# R7FA4M3AF register map
Vendor: Renesas Electronics Corporation; Series: RA4; File version: 1.40.00
CPU: CM33 r0p4, little endian, MPU, FPU, VTOR, 4 interrupt priority bits, 96 interrupts
Registers are 8-bit, read-write, reset 0x0 unless marked. A register's access mark holds for its fields unless they carry their own. Offsets are from the block's base; [hi:lo] are bit positions; {n}, {i} and the like mark numbered series.

## DAC12 — 12-bit D/A converter
Base 0x40171000
{0x0+2i} DADR{i} (i=0..1) 16-bit — D/A Data Register {i}
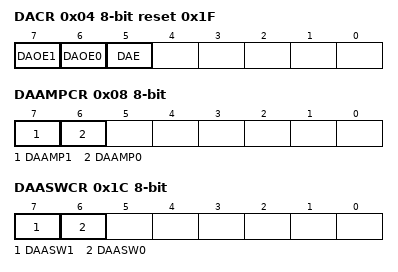
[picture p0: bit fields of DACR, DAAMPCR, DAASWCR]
0x04 DACR reset 0x1F — D/A Control Register
  [7] DAOE1 — D/A Output Enable 1
  [6] DAOE0 — D/A Output Enable 0
  [5] DAE — D/A Enable
0x05 DADPR — DADRn Format Select Register
  [7] DPSEL — DADRn Format Select
0x06 DAADSCR — D/A A/D Synchronous Start Control Register
  [7] DAADST — D/A A/D Synchronous Conversion
0x08 DAAMPCR — D/A Output Amplifier Control Register
  [7] DAAMP1 — Amplifier Control 1
  [6] DAAMP0 — Amplifier Control 0
0x1C DAASWCR — D/A Amplifier Stabilization Wait Control Register
  [7] DAASW1 — D/A Amplifier Stabilization Wait 1
  [6] DAASW0 — D/A Amplifier Stabilization Wait 0
0x10C0 DAADUSR — D/A A/D Synchronous Unit Select Register
  [1] AMADSEL1 — A/D Unit 1 Select

## TSD — Temperature Sensor Calibration Data
Base 0x407FB000
0x17C TSCDR 32-bit ro (reset mask 0xFFFF0000) — Temperature Sensor Calibration Data Register
  [15:0] TSCDR — Temperature Sensor Calibration Data

## FLAD — Data Flash
Base 0x407FC000
0x40 FCKMHZ reset 0x3C — Data Flash Access Frequency Register

## FACI — Flash/CPU Interface
Base 0x407FE000
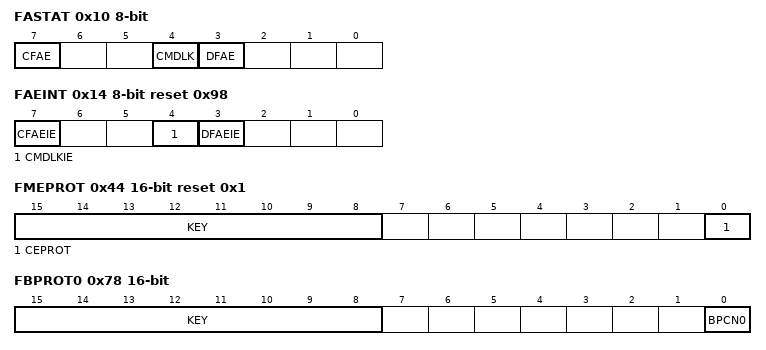
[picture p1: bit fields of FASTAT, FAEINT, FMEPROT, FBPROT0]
0x10 FASTAT — Flash Access Status Register
  [7] CFAE — Code Flash Memory Access Violation Flag
  [4] CMDLK ro — Command Lock Flag
  [3] DFAE — Data Flash Memory Access Violation Flag
0x14 FAEINT reset 0x98 — Flash Access Error Interrupt Enable Register
  [7] CFAEIE — Code Flash Memory Access Violation Interrupt Enable
  [4] CMDLKIE — Command Lock Interrupt Enable
  [3] DFAEIE — Data Flash Memory Access Violation Interrupt Enable
0x18 FRDYIE — Flash Ready Interrupt Enable Register
  [0] FRDYIE — Flash Ready Interrupt Enable
0x30 FSADDR 32-bit — FACI Command Start Address Register
  [31:0] FSADDR — Start Address for FACI Command Processing
0x34 FEADDR 32-bit — FACI Command End Address Register
  [31:0] FEADDR — End Address for FACI Command Processing
0x44 FMEPROT 16-bit reset 0x1 — Flash P/E Mode Entry Protection Register
  [15:8] KEY wo — Key Code
  [0] CEPROT — Code Flash P/E Mode Entry Protection
0x78 FBPROT0 16-bit — Flash Block Protection Register
  [15:8] KEY wo — Key Code
  [0] BPCN0 — Block Protection for Non,secure Cancel
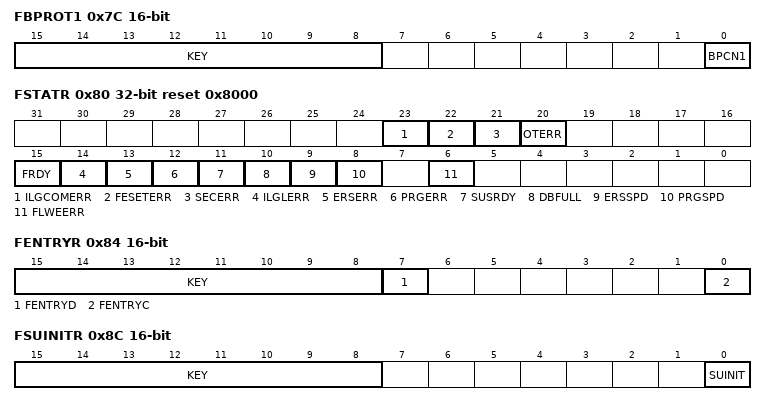
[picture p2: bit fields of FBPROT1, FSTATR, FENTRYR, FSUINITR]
0x7C FBPROT1 16-bit — Flash Block Protection for Secure Register
  [15:8] KEY wo — Key Code
  [0] BPCN1 — Block Protection for Secure Cancel
0x80 FSTATR 32-bit reset 0x8000 — Flash Status Register
  [23] ILGCOMERR ro — Illegal Command Error
  [22] FESETERR ro — FENTRY Setting Error
  [21] SECERR ro — Security Error
  [20] OTERR ro — Other Error
  [15] FRDY ro — Flash Ready Flag
  [14] ILGLERR ro — Illegal Command Error Flag
  [13] ERSERR ro — Erasure Error Flag
  [12] PRGERR ro — Programming Error Flag
  [11] SUSRDY ro — Suspend Ready Flag
  [10] DBFULL ro — Data Buffer Full Flag
  [9] ERSSPD ro — Erasure Suspend Status Flag
  [8] PRGSPD ro — Programming Suspend Status Flag
  [6] FLWEERR ro — Flash Write/Erase Protect Error Flag
0x84 FENTRYR 16-bit — Flash P/E Mode Entry Register
  [15:8] KEY wo — Key Code
  [7] FENTRYD — Data Flash P/E Mode Entry
  [0] FENTRYC — Code Flash P/E Mode Entry
0x8C FSUINITR 16-bit — Flash Sequencer Setup Initialization Register
  [15:8] KEY wo — Key Code
  [0] SUINIT — Set,Up Initialization
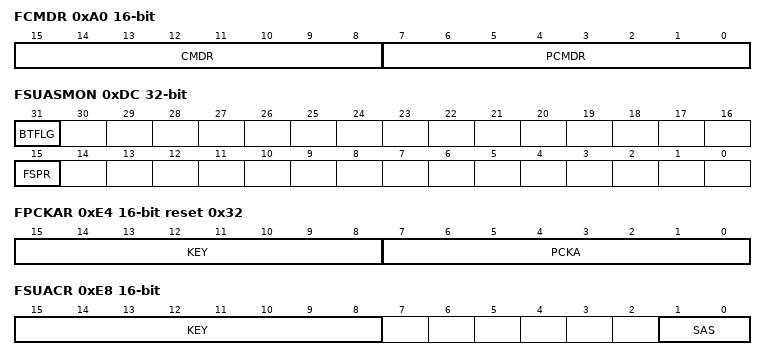
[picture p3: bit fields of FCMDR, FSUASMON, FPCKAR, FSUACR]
0xA0 FCMDR 16-bit ro — FACI Command Register
  [15:8] CMDR — Command Flag
  [7:0] PCMDR — Pre,command Flag
0xD0 FBCCNT — Blank Check Control Register
  [0] BCDIR — Blank Check Direction
0xD4 FBCSTAT — Blank Check Status Register
  [0] BCST ro — Blank Check Status Flag
0xD8 FPSADDR 32-bit — Data Flash Programming Start Address Register
  [16:0] PSADR ro — Programmed Area Start Address
0xDC FSUASMON 32-bit ro (reset mask 0x7FFF7FFF) — Flash Startup Area Select Monitor Register
  [31] BTFLG — Flag of Startup Area Select for Boot Swap
  [15] FSPR — Protection Programming Flag to set Boot Flag and Startup Area Control
0xE0 FCPSR 16-bit — Flash Sequencer Processing Switching Register
  [0] ESUSPMD — Erasure Suspend Mode
0xE4 FPCKAR 16-bit reset 0x32 — Flash Sequencer Processing Clock Notification Register
  [15:8] KEY wo — Key Code
  [7:0] PCKA — Flash Sequencer Operating Clock Notification
0xE8 FSUACR 16-bit — Flash Startup Area Control Register
  [15:8] KEY wo — Key Code
  [1:0] SAS — Startup Area Select

## QSPI — Quad Serial Peripheral Interface
Base 0x64000000
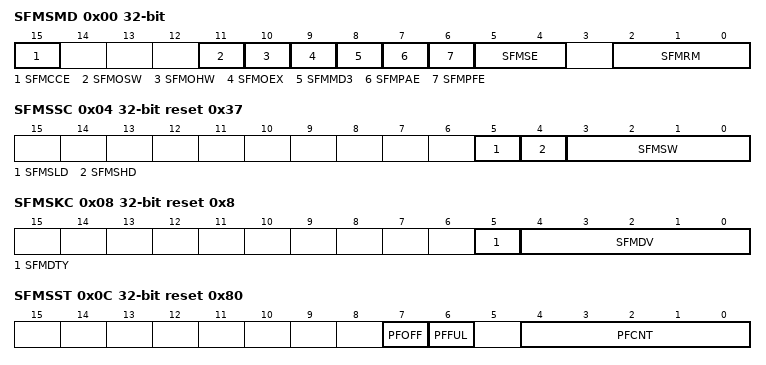
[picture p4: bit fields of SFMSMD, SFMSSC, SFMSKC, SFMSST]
0x00 SFMSMD 32-bit — Transfer Mode Control Register
  [15] SFMCCE — Read instruction code select
  [11] SFMOSW — Setup time adjustment for serial transmission
  [10] SFMOHW — Hold time adjustment for serial transmission
  [9] SFMOEX — Extension select for the I/O buffer output enable signal for the serial interface
  [8] SFMMD3 — SPI mode select.
  [7] SFMPAE — Function select for stopping prefetch at locations other than on byte boundaries
  [6] SFMPFE — Prefetch function select
  [5:4] SFMSE — QSSL extension function select after SPI bus access
  [2:0] SFMRM — Serial interface read mode select
0x04 SFMSSC 32-bit reset 0x37 — Chip Selection Control Register
  [5] SFMSLD — QSSL Signal Setup Time
  [4] SFMSHD — QSSL Signal Hold Time
  [3:0] SFMSW — Minimum High,level Width Select for QSSL Signal
0x08 SFMSKC 32-bit reset 0x8 — Clock Control Register
  [5] SFMDTY — Duty ratio correction function select for the QSPCLK signal when devided by an odd number
  [4:0] SFMDV — Serial interface reference cycle select. (Pay attention to irregularities.)
0x0C SFMSST 32-bit ro reset 0x80 — Status Register
  [7] PFOFF — Prefetch function operating state
  [6] PFFUL — Prefetch buffer state
  [4:0] PFCNT — Number of bytes of prefetched data
0x10 SFMCOM 32-bit (reset mask 0xFFFFFF00) — Communication Port Register
  [7:0] SFMD — Port for direct communication with the SPI bus
0x14 SFMCMD 32-bit — Communication Mode Control Register
  [0] DCOM — Mode select for communication with the SPI bus
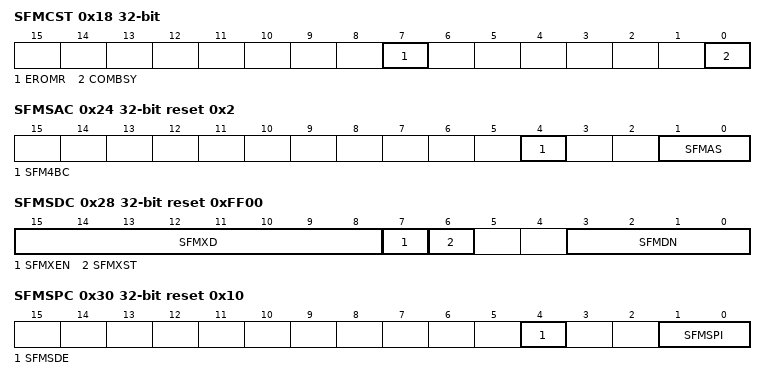
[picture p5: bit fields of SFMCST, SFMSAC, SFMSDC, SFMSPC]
0x18 SFMCST 32-bit — Communication Status Register
  [7] EROMR — ROM access detection status in direct communication mode
  [0] COMBSY ro — SPI bus cycle completion state in direct communication
0x20 SFMSIC 32-bit — Instruction Code Register
  [7:0] SFMCIC — Serial flash instruction code to substitute
0x24 SFMSAC 32-bit reset 0x2 — Address Mode Control Register
  [4] SFM4BC — Selection of instruction code automatically generated when the serial interface address width is 4 bytes
  [1:0] SFMAS — Number of address bytes select for the serial interface
0x28 SFMSDC 32-bit reset 0xFF00 — Dummy Cycle Control Register
  [15:8] SFMXD — Mode data for serial flash (Controls XIP mode.)
  [7] SFMXEN — XIP mode permission
  [6] SFMXST ro — XIP mode status
  [3:0] SFMDN — Number of dummy cycles select for Fast Read instructions
0x30 SFMSPC 32-bit reset 0x10 — SPI Protocol Control Register
  [4] SFMSDE — QSPCLK extended selection bit when switching I/O of QIOn pin
  [1:0] SFMSPI — SPI protocol select
0x34 SFMPMD 32-bit — Port Control Register
  [2] SFMWPL — WP pin level specification
0x804 SFMCNT1 32-bit — External QSPI Address Register
  [31:26] QSPI_EXT — Bank switching address
